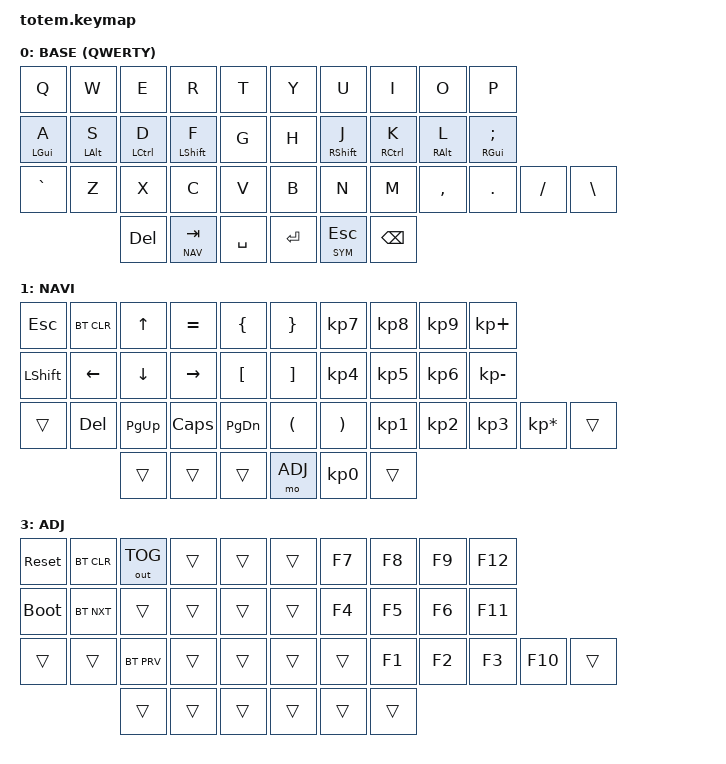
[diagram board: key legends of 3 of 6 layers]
#include <behaviors.dtsi>
#include <dt-bindings/zmk/keys.h>
#include <dt-bindings/zmk/bt.h>
#include <dt-bindings/zmk/outputs.h>

#define BASE 0
#define NAV  1
#define SYM  2
#define ADJ  3
#define TVP1 4
#define TVP2 5

&mt {
  quick-tap-ms = <100>;
  global-quick-tap;
  flavor = "tap-preferred";
  tapping-term-ms = <170>;
};

/ {
     combos {
            compatible = "zmk,combos";
            combo_esc {
                timeout-ms = <50>;
                key-positions = <0 1>; // Q W on QWERTY
                bindings = <&kp ESC>;
            };
            combo_tvp {
                timeout-ms = <100>;
                key-positions = <11 12 13>; // S D F (home row mod-taps) on QWERTY
                bindings = <&tog TVP1>;
            };
    };

    macros {
        gif: gif {
            label = "giphy";
            compatible = "zmk,behavior-macro";
            #binding-cells = <0>;
            bindings
                = <&macro_press &kp LSHFT>
                , <&macro_tap &kp N2>
                , <&macro_release &kp LSHFT>
                , <&macro_tap &kp G &kp I &kp F>
                ;
        };
    };

        keymap {
                compatible = "zmk,keymap";

                base_layer {
                    label= "BASE (QWERTY)";
                    bindings = <
                        &kp Q          &kp W          &kp E          &kp R          &kp T              &kp Y          &kp U          &kp I           &kp O         &kp P
                        &mt LGUI A     &mt LALT S     &mt LCTRL D    &mt LSHFT F    &kp G              &kp H          &mt RSHFT J    &mt RCTRL K     &mt RALT L    &mt RGUI SEMI
                        &kp GRAVE      &kp Z          &kp X          &kp C          &kp V          &kp B              &kp N          &kp M          &kp COMMA     &kp DOT     &kp FSLH   &kp BSLH
                                                       &kp DEL     &lt NAV TAB   &kp SPACE         &kp RET     &lt SYM ESC   &kp BSPC
                    >;
                };

                nav_layer {
                    label= "NAVI";
                    bindings = <
                        &kp ESC     &bt BT_CLR  &kp UP      &kp EQUAL   &kp LBRC        &kp RBRC    &kp KP_N7   &kp KP_N8   &kp KP_N9   &kp KP_PLUS
                        &kp LSHFT   &kp LEFT    &kp DOWN    &kp RIGHT   &kp LBKT        &kp RBKT    &kp KP_N4   &kp KP_N5   &kp KP_N6   &kp KP_MINUS
                        &trans      &kp DEL     &kp PG_UP   &kp CAPS    &kp PG_DN   &kp LPAR        &kp RPAR    &kp KP_N1   &kp KP_N2   &kp KP_N3   &kp KP_MULTIPLY &trans
                                                        &trans      &trans      &trans          &mo ADJ     &kp KP_N0   &trans
                    >;
                };

                sim_layer {
                    label= "SYM";
                    bindings = <
                        &kp EXCL    &kp AT      &kp HASH    &kp DLLR    &kp PRCNT       &kp CARET   &kp AMPER   &kp RALT U  &kp SQT     &kp DQT
                        &kp RALT A  &trans      &kp RALT S  &trans      &trans          &kp C_MUTE  &kp LSHFT RALT N4 &kp RALT N5 &kp RALT N4  &kp RALT O
                        &trans      &kp RALT F18 &kp RALT F19 &trans      &trans      &trans          &kp C_VOL_DN &kp C_VOL_UP &kp C_PREV &kp C_NEXT  &kp BSLH   &trans
                                                        &trans      &gif        &mo ADJ         &trans      &kp C_PP    &trans
                    >;
                };

                adjust_layer {
                    label= "ADJ";
                    bindings = <
                        &sys_reset  &bt BT_CLR &out OUT_TOG &trans      &trans          &trans      &kp F7      &kp F8      &kp F9      &kp F12
                        &bootloader &bt BT_NXT  &trans      &trans      &trans          &trans      &kp F4      &kp F5      &kp F6      &kp F11
                        &trans      &trans      &bt BT_PRV  &trans      &trans      &trans          &trans      &kp F1      &kp F2      &kp F3      &kp F10     &trans
                                                        &trans      &trans      &trans          &trans      &trans      &trans
                    >;
                };

                tvp1_layer {
                    label= "TVP 1";
                    bindings = <
                        &kp TAB     &kp I       &kp LCTRL LALT &kp O      &kp LCTRL F20     &none       &none       &none       &none       &none
                        &lt TVP2 L  &kp LEFT    &kp LALT    &kp RIGHT   &kp SPACE       &none       &none       &none       &none       &none
                        &kp J       &kp LSHFT   &kp LCTRL C   &kp BSPC    &kp LCTRL V   &kp LCTRL F19     &none       &none       &none       &none       &none       &none
                                                        &trans      &kp LCTRL F14 &kp LCTRL F13     &none       &none       &none
                    >;
                };

                tvp2_layer {
                    label= "TVP 2";
                    bindings = <
                        &kp LCTRL F18 &kp LSHFT I  &kp LSHFT HOME &kp LSHFT O   &kp LSHFT F       &trans      &kp F7      &kp F8      &kp F9      &kp F12
                        &trans      &kp LSHFT LEFT &kp LCTRL F17 &kp LSHFT RIGHT &kp RET      &trans      &kp F4      &kp F5      &kp F6      &kp F11
                        &trans      &kp J       &kp LSHFT C   &kp LCTRL F16 &kp LSHFT V   &kp LCTRL F15     &trans      &kp F1      &kp F2      &kp F3      &kp F10     &trans
                                                        &trans      &kp LCTRL F12 &kp LCTRL F11     &trans      &trans      &trans
                    >;
                };
        };
};
